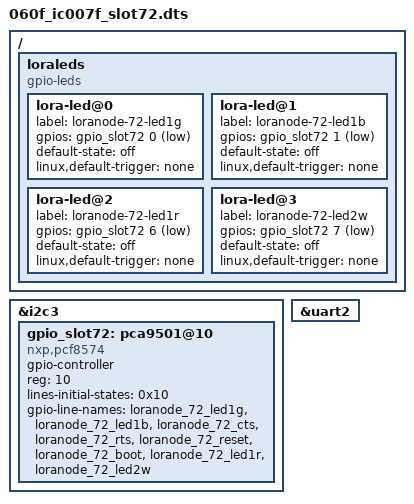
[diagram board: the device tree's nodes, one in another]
/dts-v1/;


/plugin/;

/ {
	fragment@0 {
		target = <&i2c3>;
		__overlay__ {
			#address-cells = <1>;
			#size-cells = <0>;
			gpio_slot72: pca9501@10 {
				compatible = "nxp,pcf8574";
				gpio-controller;
				#gpio-cells = <2>;
				reg = <10>;
				lines-initial-states = <0x10>;
                gpio-line-names ="loranode_72_led1g",
                "loranode_72_led1b",
                "loranode_72_cts",
                "loranode_72_rts",
                "loranode_72_reset",
                "loranode_72_boot",
                "loranode_72_led1r",
                "loranode_72_led2w";
                
			};
		};
	};

	fragment@3 {
		
		target = <&uart2>;
		__overlay__ {
			status = "okay";
		};

	};

	fragment@4 {
		target-path = "/";
		__overlay__ {
			loraleds {
				compatible = "gpio-leds";
				lora-led@0 {
					label = "loranode-72-led1g";
					gpios = <&gpio_slot72 0 1>;
					default-state = "off";
					linux,default-trigger = "none";
				};
				lora-led@1 {
					label = "loranode-72-led1b";
					gpios = <&gpio_slot72 1 1>;
					default-state = "off";
					linux,default-trigger = "none";
				};				
				lora-led@2 {
					label = "loranode-72-led1r";
					gpios = <&gpio_slot72 6 1>;
					default-state = "off";
					linux,default-trigger = "none";
				};
				lora-led@3 {
					label = "loranode-72-led2w";
					gpios = <&gpio_slot72 7 1>;
					default-state = "off";
					linux,default-trigger = "none";
				};
			};
		};
	};
};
